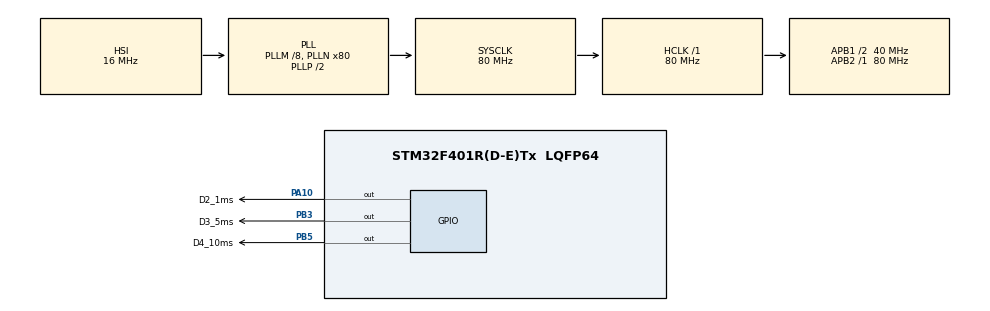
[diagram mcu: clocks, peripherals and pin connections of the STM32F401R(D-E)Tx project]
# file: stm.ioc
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Mcu.Family=STM32F4
Mcu.Name=STM32F401R(D-E)Tx
Mcu.Package=LQFP64
Mcu.UserConstants=timeKeeper,0
NVIC.PriorityGroup=NVIC_PRIORITYGROUP_4
NVIC.TIM2_IRQn=true\:0\:0\:false\:false\:true\:true\:true\:true
PA10.GPIO_Label=D2_1ms
PA10.GPIO_Speed=GPIO_SPEED_FREQ_MEDIUM
PA10.Signal=GPIO_Output
PB3.GPIO_Label=D3_5ms
PB3.GPIO_Speed=GPIO_SPEED_FREQ_MEDIUM
PB3.Signal=GPIO_Output
PB5.GPIO_Label=D4_10ms
PB5.GPIO_Speed=GPIO_SPEED_FREQ_MEDIUM
PB5.Signal=GPIO_Output
PH0\ -\ OSC_IN.Mode=HSE-External-Oscillator
PH0\ -\ OSC_IN.Signal=RCC_OSC_IN
PH1\ -\ OSC_OUT.Mode=HSE-External-Oscillator
PH1\ -\ OSC_OUT.Signal=RCC_OSC_OUT
ProjectManager.HeapSize=0x200
ProjectManager.StackSize=0x400
ProjectManager.TargetToolchain=STM32CubeIDE
RCC.48MHZClocksFreq_Value=40000000
RCC.AHBFreq_Value=80000000
RCC.APB1CLKDivider=RCC_HCLK_DIV2
RCC.APB1Freq_Value=40000000
RCC.APB1TimFreq_Value=80000000
RCC.APB2Freq_Value=80000000
RCC.APB2TimFreq_Value=80000000
RCC.CortexFreq_Value=80000000
RCC.HCLKFreq_Value=80000000
RCC.HSE_VALUE=25000000
RCC.HSI_VALUE=16000000
RCC.LSE_VALUE=32768
RCC.PLLM=8
RCC.PLLN=80
RCC.SYSCLKFreq_VALUE=80000000
RCC.SYSCLKSource=RCC_SYSCLKSOURCE_PLLCLK
RCC.VCOOutputFreq_Value=160000000
TIM2.AutoReloadPreload=TIM_AUTORELOAD_PRELOAD_ENABLE
TIM2.ClockDivision=TIM_CLOCKDIVISION_DIV1
TIM2.Period=1
TIM2.Prescaler=15999
TIM2.TIM_MasterOutputTrigger=TIM_TRGO_ENABLE
VP_TIM2_VS_ClockSourceINT.Mode=Internal
board=custom

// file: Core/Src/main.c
/* USER CODE BEGIN Header */
/**
  ******************************************************************************
  * @file           : main.c
  * @brief          : Main program body
  ******************************************************************************
  * @attention
  *
  * Copyright (c) 2024 STMicroelectronics.
  * All rights reserved.
  *
  * This software is licensed under terms that can be found in the LICENSE file
  * in the root directory of this software component.
  * If no LICENSE file comes with this software, it is provided AS-IS.
  *
  ******************************************************************************
  */
/* USER CODE END Header */
#include "main.h"

/* USER CODE BEGIN Includes */
#include "OsMain.h"
#include "stm32f4xx_hal.h"

/* USER CODE END Includes */

TIM_HandleTypeDef htim2;

void SystemClock_Config(void);
static void MX_GPIO_Init(void);
static void MX_TIM2_Init(void);

int main(void)
{

  /* MCU Configuration--------------------------------------------------------*/

  /* Reset of all peripherals, Initializes the Flash interface and the Systick. */
  HAL_Init();

  /* Configure the system clock */
  SystemClock_Config();

  /* Initialize all configured peripherals */
  MX_GPIO_Init();
  MX_TIM2_Init();
  /* USER CODE BEGIN 2 */
  HAL_TIM_Base_Start_IT(&htim2);
  /* USER CODE END 2 */

  /* Infinite loop */
  while (1)
  {
	  OsTaskRun();
  }
}

void HAL_TIM_PeriodElapsedCallback(TIM_HandleTypeDef* htim)
{
	scheduler_run();
}

void SystemClock_Config(void)
{
  RCC_OscInitTypeDef RCC_OscInitStruct = {0};
  RCC_ClkInitTypeDef RCC_ClkInitStruct = {0};

  /** Configure the main internal regulator output voltage
  */
  __HAL_RCC_PWR_CLK_ENABLE();
  __HAL_PWR_VOLTAGESCALING_CONFIG(PWR_REGULATOR_VOLTAGE_SCALE2);

  /** Initializes the RCC Oscillators according to the specified parameters
  * in the RCC_OscInitTypeDef structure.
  */
  RCC_OscInitStruct.OscillatorType = RCC_OSCILLATORTYPE_HSI;
  RCC_OscInitStruct.HSIState = RCC_HSI_ON;
  RCC_OscInitStruct.HSICalibrationValue = RCC_HSICALIBRATION_DEFAULT;
  RCC_OscInitStruct.PLL.PLLState = RCC_PLL_ON;
  RCC_OscInitStruct.PLL.PLLSource = RCC_PLLSOURCE_HSI;
  RCC_OscInitStruct.PLL.PLLM = 8;
  RCC_OscInitStruct.PLL.PLLN = 80;
  RCC_OscInitStruct.PLL.PLLP = RCC_PLLP_DIV2;
  RCC_OscInitStruct.PLL.PLLQ = 4;
  if (HAL_RCC_OscConfig(&RCC_OscInitStruct) != HAL_OK)
  {
    Error_Handler();
  }

  /** Initializes the CPU, AHB and APB buses clocks
  */
  RCC_ClkInitStruct.ClockType = RCC_CLOCKTYPE_HCLK|RCC_CLOCKTYPE_SYSCLK
                              |RCC_CLOCKTYPE_PCLK1|RCC_CLOCKTYPE_PCLK2;
  RCC_ClkInitStruct.SYSCLKSource = RCC_SYSCLKSOURCE_PLLCLK;
  RCC_ClkInitStruct.AHBCLKDivider = RCC_SYSCLK_DIV1;
  RCC_ClkInitStruct.APB1CLKDivider = RCC_HCLK_DIV2;
  RCC_ClkInitStruct.APB2CLKDivider = RCC_HCLK_DIV1;

  if (HAL_RCC_ClockConfig(&RCC_ClkInitStruct, FLASH_LATENCY_2) != HAL_OK)
  {
    Error_Handler();
  }
}

static void MX_TIM2_Init(void)
{

  TIM_ClockConfigTypeDef sClockSourceConfig = {0};
  TIM_MasterConfigTypeDef sMasterConfig = {0};

  htim2.Instance = TIM2;
  htim2.Init.Prescaler = 15999;
  htim2.Init.CounterMode = TIM_COUNTERMODE_UP;
  htim2.Init.Period = 1;
  htim2.Init.ClockDivision = TIM_CLOCKDIVISION_DIV1;
  htim2.Init.AutoReloadPreload = TIM_AUTORELOAD_PRELOAD_ENABLE;
  if (HAL_TIM_Base_Init(&htim2) != HAL_OK)
  {
    Error_Handler();
  }
  sClockSourceConfig.ClockSource = TIM_CLOCKSOURCE_INTERNAL;
  if (HAL_TIM_ConfigClockSource(&htim2, &sClockSourceConfig) != HAL_OK)
  {
    Error_Handler();
  }
  sMasterConfig.MasterOutputTrigger = TIM_TRGO_ENABLE;
  sMasterConfig.MasterSlaveMode = TIM_MASTERSLAVEMODE_DISABLE;
  if (HAL_TIMEx_MasterConfigSynchronization(&htim2, &sMasterConfig) != HAL_OK)
  {
    Error_Handler();
  }

}

static void MX_GPIO_Init(void)
{
  GPIO_InitTypeDef GPIO_InitStruct = {0};

  /* GPIO Ports Clock Enable */
  __HAL_RCC_GPIOH_CLK_ENABLE();
  __HAL_RCC_GPIOA_CLK_ENABLE();
  __HAL_RCC_GPIOB_CLK_ENABLE();

  /*Configure GPIO pin Output Level */
  HAL_GPIO_WritePin(D2_1ms_GPIO_Port, D2_1ms_Pin, GPIO_PIN_RESET);

  /*Configure GPIO pin Output Level */
  HAL_GPIO_WritePin(GPIOB, D3_5ms_Pin|D4_10ms_Pin, GPIO_PIN_RESET);

  /*Configure GPIO pin : D2_1ms_Pin */
  GPIO_InitStruct.Pin = D2_1ms_Pin;
  GPIO_InitStruct.Mode = GPIO_MODE_OUTPUT_PP;
  GPIO_InitStruct.Pull = GPIO_NOPULL;
  GPIO_InitStruct.Speed = GPIO_SPEED_FREQ_MEDIUM;
  HAL_GPIO_Init(D2_1ms_GPIO_Port, &GPIO_InitStruct);

  /*Configure GPIO pins : D3_5ms_Pin D4_10ms_Pin */
  GPIO_InitStruct.Pin = D3_5ms_Pin|D4_10ms_Pin;
  GPIO_InitStruct.Mode = GPIO_MODE_OUTPUT_PP;
  GPIO_InitStruct.Pull = GPIO_NOPULL;
  GPIO_InitStruct.Speed = GPIO_SPEED_FREQ_MEDIUM;
  HAL_GPIO_Init(GPIOB, &GPIO_InitStruct);

}

void Error_Handler(void)
{
  __disable_irq();
  while (1)
  {
  }
}
